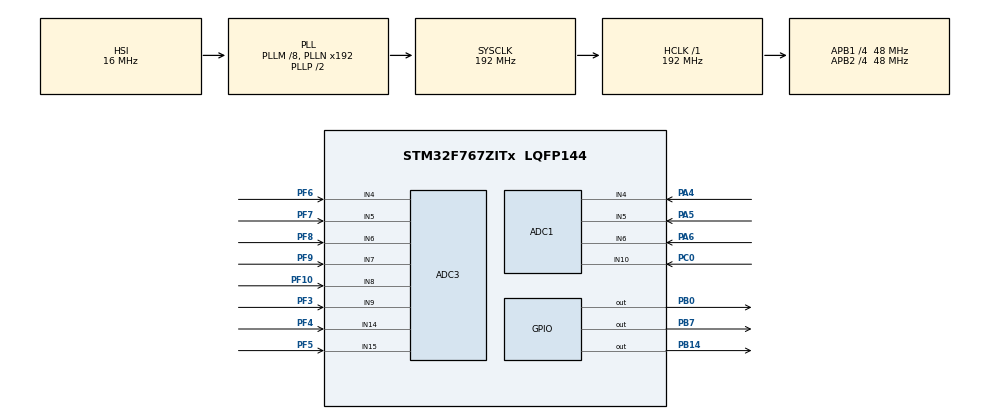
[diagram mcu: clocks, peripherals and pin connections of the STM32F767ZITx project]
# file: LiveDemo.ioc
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ADC1.Channel-0\#ChannelRegularConversion=ADC_CHANNEL_4
ADC1.ClockPrescaler=ADC_CLOCK_SYNC_PCLK_DIV4
ADC1.NbrOfConversionFlag=1
ADC1.Rank-0\#ChannelRegularConversion=1
ADC1.SamplingTime-0\#ChannelRegularConversion=ADC_SAMPLETIME_3CYCLES
ADC1.master=1
ADC2.Channel-0\#ChannelRegularConversion=ADC_CHANNEL_4
ADC2.ClockPrescaler=ADC_CLOCK_SYNC_PCLK_DIV4
ADC2.NbrOfConversionFlag=1
ADC2.Rank-0\#ChannelRegularConversion=1
ADC2.SamplingTime-0\#ChannelRegularConversion=ADC_SAMPLETIME_3CYCLES
ADC3.Channel-0\#ChannelRegularConversion=ADC_CHANNEL_4
ADC3.ClockPrescaler=ADC_CLOCK_SYNC_PCLK_DIV4
ADC3.NbrOfConversionFlag=1
ADC3.Rank-0\#ChannelRegularConversion=1
ADC3.SamplingTime-0\#ChannelRegularConversion=ADC_SAMPLETIME_3CYCLES
Mcu.Family=STM32F7
Mcu.Name=STM32F767ZITx
Mcu.Package=LQFP144
NVIC.PriorityGroup=NVIC_PRIORITYGROUP_4
NVIC.TIM1_UP_TIM10_IRQn=true\:0\:0\:false\:false\:true\:true\:true
NVIC.TIM2_IRQn=true\:0\:0\:false\:false\:true\:true\:true
NVIC.TIM3_IRQn=true\:0\:0\:false\:false\:true\:true\:true
PA4.Signal=ADCx_IN4
PA5.Signal=ADCx_IN5
PA6.Signal=ADCx_IN6
PB0.Signal=GPIO_Output
PB14.Signal=GPIO_Output
PB7.Signal=GPIO_Output
PC0.Signal=ADCx_IN10
PF10.Mode=IN8
PF10.Signal=ADC3_IN8
PF3.Mode=IN9
PF3.Signal=ADC3_IN9
PF4.Mode=IN14
PF4.Signal=ADC3_IN14
PF5.Mode=IN15
PF5.Signal=ADC3_IN15
PF6.Mode=IN4
PF6.Signal=ADC3_IN4
PF7.Mode=IN5
PF7.Signal=ADC3_IN5
PF8.Mode=IN6
PF8.Signal=ADC3_IN6
PF9.Mode=IN7
PF9.Signal=ADC3_IN7
PH0/OSC_IN.Mode=HSE-External-Oscillator
PH0/OSC_IN.Signal=RCC_OSC_IN
PH1/OSC_OUT.Mode=HSE-External-Oscillator
PH1/OSC_OUT.Signal=RCC_OSC_OUT
ProjectManager.HeapSize=0x200
ProjectManager.StackSize=0x400
ProjectManager.TargetToolchain=STM32CubeIDE
RCC.48MHZClocksFreq_Value=24000000
RCC.AHBFreq_Value=192000000
RCC.APB1CLKDivider=RCC_HCLK_DIV4
RCC.APB1Freq_Value=48000000
RCC.APB1TimFreq_Value=96000000
RCC.APB2CLKDivider=RCC_HCLK_DIV4
RCC.APB2Freq_Value=48000000
RCC.APB2TimFreq_Value=96000000
RCC.CortexFreq_Value=192000000
RCC.HCLKFreq_Value=192000000
RCC.HSE_VALUE=8000000
RCC.HSI_VALUE=16000000
RCC.LSE_VALUE=32768
RCC.PLLM=8
RCC.PLLMUL=RCC_PLL_MUL9
RCC.PLLQ=8
RCC.PRESCALERUSB=RCC_USBCLKSOURCE_PLL_DIV1_5
RCC.SDMMCClockSelection=RCC_SDMMC1CLKSOURCE_CLK48
RCC.SYSCLKFreq_VALUE=192000000
RCC.SYSCLKSource=RCC_SYSCLKSOURCE_PLLCLK
RCC.SYSCLKSourceVirtual=RCC_SYSCLKSOURCE_PLLCLK
RCC.USBFreq_Value=48000000
RCC.VCOOutputFreq_Value=384000000
SH.ADCx_IN10.0=ADC1_IN10,IN10
SH.ADCx_IN10.1=ADC2_IN10,IN10
SH.ADCx_IN10.2=ADC3_IN10,IN10
SH.ADCx_IN4.0=ADC1_IN4,IN4
SH.ADCx_IN4.1=ADC2_IN4,IN4
SH.ADCx_IN5.0=ADC1_IN5,IN5
SH.ADCx_IN5.1=ADC2_IN5,IN5
SH.ADCx_IN6.0=ADC1_IN6,IN6
SH.ADCx_IN6.1=ADC2_IN6,IN6
TIM1.Prescaler=9599
TIM2.Prescaler=9600
TIM3.Prescaler=9599
VP_TIM1_VS_ClockSourceINT.Mode=Internal
VP_TIM2_VS_ClockSourceINT.Mode=Internal
VP_TIM3_VS_ClockSourceINT.Mode=Internal
board=custom

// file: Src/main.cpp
/* USER CODE BEGIN Header */
/**
  ******************************************************************************
  * @file           : main.c
  * @brief          : Main program body
  ******************************************************************************
  * @attention
  *
  * <h2><center>&copy; Copyright (c) 2019 STMicroelectronics.
  * All rights reserved.</center></h2>
  *
  * This software component is licensed by ST under BSD 3-Clause license,
  * the "License"; You may not use this file except in compliance with the
  * License. You may obtain a copy of the License at:
  *                        opensource.org/licenses/BSD-3-Clause
  *
  ******************************************************************************
  */
/* USER CODE END Header */

#include "main.h"
#include "adc.h"
#include "tim.h"
#include "gpio.h"

/* USER CODE BEGIN Includes */
#include "fsm_driver.hpp"
/* USER CODE END Includes */

void SystemClock_Config(void);

int main(void)
{

  /* MCU Configuration--------------------------------------------------------*/

  /* Reset of all peripherals, Initializes the Flash interface and the Systick. */
  HAL_Init();

  /* Configure the system clock */
  SystemClock_Config();

  /* Initialize all configured peripherals */
  MX_GPIO_Init();
  MX_ADC1_Init();
  MX_ADC2_Init();
  MX_ADC3_Init();
  MX_TIM1_Init();
  MX_TIM2_Init();
  MX_TIM3_Init();
  /* USER CODE BEGIN 2 */
  start_fsm_driver();
  /* USER CODE END 2 */

  /* Infinite loop */
  while (1)
  {

  }
}

void SystemClock_Config(void)
{
  RCC_OscInitTypeDef RCC_OscInitStruct = {0};
  RCC_ClkInitTypeDef RCC_ClkInitStruct = {0};

  /** Configure the main internal regulator output voltage
  */
  __HAL_RCC_PWR_CLK_ENABLE();
  __HAL_PWR_VOLTAGESCALING_CONFIG(PWR_REGULATOR_VOLTAGE_SCALE1);
  /** Initializes the CPU, AHB and APB busses clocks
  */
  RCC_OscInitStruct.OscillatorType = RCC_OSCILLATORTYPE_HSI;
  RCC_OscInitStruct.HSIState = RCC_HSI_ON;
  RCC_OscInitStruct.HSICalibrationValue = RCC_HSICALIBRATION_DEFAULT;
  RCC_OscInitStruct.PLL.PLLState = RCC_PLL_ON;
  RCC_OscInitStruct.PLL.PLLSource = RCC_PLLSOURCE_HSI;
  RCC_OscInitStruct.PLL.PLLM = 8;
  RCC_OscInitStruct.PLL.PLLN = 192;
  RCC_OscInitStruct.PLL.PLLP = RCC_PLLP_DIV2;
  RCC_OscInitStruct.PLL.PLLQ = 8;
  if (HAL_RCC_OscConfig(&RCC_OscInitStruct) != HAL_OK)
  {
    Error_Handler();
  }
  /** Activate the Over-Drive mode
  */
  if (HAL_PWREx_EnableOverDrive() != HAL_OK)
  {
    Error_Handler();
  }
  /** Initializes the CPU, AHB and APB busses clocks
  */
  RCC_ClkInitStruct.ClockType = RCC_CLOCKTYPE_HCLK|RCC_CLOCKTYPE_SYSCLK
                              |RCC_CLOCKTYPE_PCLK1|RCC_CLOCKTYPE_PCLK2;
  RCC_ClkInitStruct.SYSCLKSource = RCC_SYSCLKSOURCE_PLLCLK;
  RCC_ClkInitStruct.AHBCLKDivider = RCC_SYSCLK_DIV1;
  RCC_ClkInitStruct.APB1CLKDivider = RCC_HCLK_DIV4;
  RCC_ClkInitStruct.APB2CLKDivider = RCC_HCLK_DIV4;

  if (HAL_RCC_ClockConfig(&RCC_ClkInitStruct, FLASH_LATENCY_6) != HAL_OK)
  {
    Error_Handler();
  }
}

void Error_Handler(void)
{
}

/************************ (C) COPYRIGHT STMicroelectronics *****END OF FILE****/
